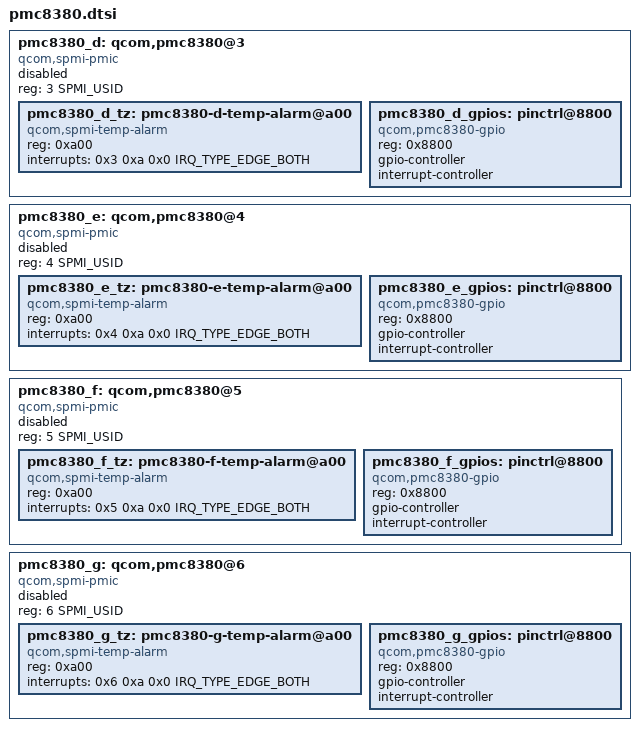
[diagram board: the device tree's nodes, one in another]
// SPDX-License-Identifier: BSD-3-Clause
/*
 * Copyright (c) Qualcomm Technologies, Inc. and/or its subsidiaries.
 */

#include <dt-bindings/interrupt-controller/irq.h>
#include <dt-bindings/spmi/spmi.h>

pmc8380_d: qcom,pmc8380@3 {
	compatible = "qcom,spmi-pmic";
	reg = <3 SPMI_USID>;
	#address-cells = <1>;
	#size-cells = <0>;
	status = "disabled";

	pmc8380_d_tz: pmc8380-d-temp-alarm@a00 {
		compatible = "qcom,spmi-temp-alarm";
		reg = <0xa00>;
		interrupts = <0x3 0xa 0x0 IRQ_TYPE_EDGE_BOTH>;
		#thermal-sensor-cells = <0>;
	};

	pmc8380_d_gpios: pinctrl@8800 {
		compatible = "qcom,pmc8380-gpio";
		reg = <0x8800>;
		gpio-controller;
		#gpio-cells = <2>;
		interrupt-controller;
		#interrupt-cells = <2>;
	};
};

pmc8380_e: qcom,pmc8380@4 {
	compatible = "qcom,spmi-pmic";
	reg = <4 SPMI_USID>;
	#address-cells = <1>;
	#size-cells = <0>;
	status = "disabled";

	pmc8380_e_tz: pmc8380-e-temp-alarm@a00 {
		compatible = "qcom,spmi-temp-alarm";
		reg = <0xa00>;
		interrupts = <0x4 0xa 0x0 IRQ_TYPE_EDGE_BOTH>;
		#thermal-sensor-cells = <0>;
	};

	pmc8380_e_gpios: pinctrl@8800 {
		compatible = "qcom,pmc8380-gpio";
		reg = <0x8800>;
		gpio-controller;
		#gpio-cells = <2>;
		interrupt-controller;
		#interrupt-cells = <2>;
	};
};

pmc8380_f: qcom,pmc8380@5 {
	compatible = "qcom,spmi-pmic";
	reg = <5 SPMI_USID>;
	#address-cells = <1>;
	#size-cells = <0>;
	status = "disabled";

	pmc8380_f_tz: pmc8380-f-temp-alarm@a00 {
		compatible = "qcom,spmi-temp-alarm";
		reg = <0xa00>;
		interrupts = <0x5 0xa 0x0 IRQ_TYPE_EDGE_BOTH>;
		#thermal-sensor-cells = <0>;
	};

	pmc8380_f_gpios: pinctrl@8800 {
		compatible = "qcom,pmc8380-gpio";
		reg = <0x8800>;
		gpio-controller;
		#gpio-cells = <2>;
		interrupt-controller;
		#interrupt-cells = <2>;
	};
};

pmc8380_g: qcom,pmc8380@6 {
	compatible = "qcom,spmi-pmic";
	reg = <6 SPMI_USID>;
	#address-cells = <1>;
	#size-cells = <0>;
	status = "disabled";

	pmc8380_g_tz: pmc8380-g-temp-alarm@a00 {
		compatible = "qcom,spmi-temp-alarm";
		reg = <0xa00>;
		interrupts = <0x6 0xa 0x0 IRQ_TYPE_EDGE_BOTH>;
		#thermal-sensor-cells = <0>;
	};

	pmc8380_g_gpios: pinctrl@8800 {
		compatible = "qcom,pmc8380-gpio";
		reg = <0x8800>;
		gpio-controller;
		#gpio-cells = <2>;
		interrupt-controller;
		#interrupt-cells = <2>;
	};
};
